# MSPM0L134X register map
Vendor: Texas Instruments; File version: This preliminary header file does not have a version number - build date: 2023-02-21 16:43:37
ARM Device
CPU: CM0 r0p1, little endian, MPU, no FPU, 3 interrupt priority bits
Registers are 32-bit, read-write, reset 0x0 unless marked. A register's access mark holds for its fields unless they carry their own. Offsets are from the block's base; lines under a group give offsets from that group; [hi:lo] are bit positions; {n}, {i} and the like mark numbered series; 'fields as' and 'values as' point back to an identical list; <NAME> marks a mode.

## Memory map
0x40004000 ADC0 size 0x2000 — PERIPHERALREGION
0x40008000 COMP0 size 0x1F00 — PERIPHERALREGION
0x40020000 OPA0 size 0x1F00 — PERIPHERALREGION
0x40022000 OPA1 size 0x1F00 — PERIPHERALREGION
0x40030000 VREF size 0x1F00 — PERIPHERALREGION
0x40080000 WWDT0 size 0x1500 — WWDT
0x40084000 TIMG0 size 0x1F00 — PERIPHERALREGION
0x40086000 TIMG1 size 0x1F00 — PERIPHERALREGION
0x40088000 TIMG2 size 0x1F00 — PERIPHERALREGION
0x4008C000 TIMG4 size 0x1F00 — PERIPHERALREGION
0x400A0000 GPIOA size 0x1F00 — PERIPHERALREGION
0x400AF000 SYSCTL size 0x2C64 — mem_map
0x400C7000 DEBUGSS size 0x1F00 — DSSM
0x400CD000 FLASHCTL size 0x2000 — F65NW
0x400F0000 I2C0 size 0x1F00 — PERIPHERALREGION
0x400F2000 I2C1 size 0x1F00 — PERIPHERALREGION
0x40100000 UART1 size 0x1F00 — PERIPHERALREGION
0x40108000 UART0 size 0x1F00 — PERIPHERALREGION
0x40400000 CPUSS size 0x1F00 — CPUSSMMR
0x40424000 WUC size 0x500 — PERIPHERALREGION
0x40428000 IOMUX size 0x2000 — PERIPHERALREGION
0x4042A000 DMA size 0x1F00 — PERIPHERALREGION
0x40440000 CRC size 0x2000 — PERIPHERALREGION
0x40468000 SPI0 size 0x1F00 — PERIPHERALREGION
0x4055A000 ADC0_SVT size 0x1000 — PERIPHERALREGIONSVT

## VREF — PERIPHERALREGION
Base 0x40030000
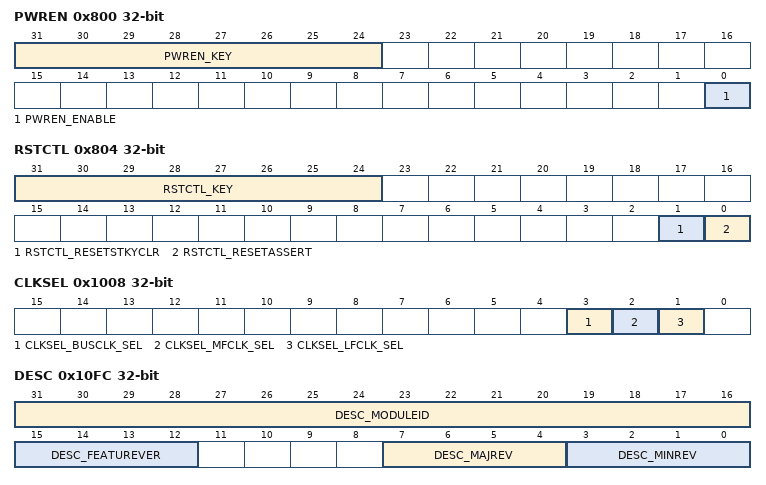
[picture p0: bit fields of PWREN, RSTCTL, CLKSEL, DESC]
0x800 PWREN — Power enable
  [31:24] PWREN_KEY wo — KEY to allow Power State Change
    38=PWREN_KEY_UNLOCK_W (_TO_UNLOCK_W_)
  [0] PWREN_ENABLE — Enable the power
    0=PWREN_ENABLE_DISABLE (DISABLE); 1=PWREN_ENABLE_ENABLE (ENABLE)
0x804 RSTCTL wo — Reset Control
  [31:24] RSTCTL_KEY — Unlock key
    177=RSTCTL_KEY_UNLOCK_W (_TO_UNLOCK_W_)
  [1] RSTCTL_RESETSTKYCLR — Clear the RESETSTKY bit in the STAT register
    0=RSTCTL_RESETSTKYCLR_NOP (NOP); 1=RSTCTL_RESETSTKYCLR_CLR (CLR)
  [0] RSTCTL_RESETASSERT — Assert reset to the peripheral
    0=RSTCTL_RESETASSERT_NOP (NOP); 1=RSTCTL_RESETASSERT_ASSERT (ASSERT)
0x814 STAT ro — Status Register
  [16] STAT_RESETSTKY — This bit indicates, if the peripheral was reset, since this bit was cleared by RESETSTKYCLR in the RSTCTL register
    0=STAT_RESETSTKY_NORES (NORES); 1=STAT_RESETSTKY_RESET (RESET)
0x1000 CLKDIV — Clock Divider
  [2:0] CLKDIV_RATIO — Selects divide ratio of module clock
0x1008 CLKSEL — Clock Selection
  [3] CLKSEL_BUSCLK_SEL — Selects BUSCLK as clock source if enabled
  [2] CLKSEL_MFCLK_SEL — Selects MFCLK as clock source if enabled
  [1] CLKSEL_LFCLK_SEL — Selects LFCLK as clock source if enabled
0x10FC DESC ro — Module Description
  [31:16] DESC_MODULEID — Module identification contains a unique peripheral identification number. The assignments are maintained in a central database for all of the platform modules to ensure uniqueness.
  [15:12] DESC_FEATUREVER — Feature Set for the module *instance*
  [7:4] DESC_MAJREV — Major rev of the IP
  [3:0] DESC_MINREV — Minor rev of the IP
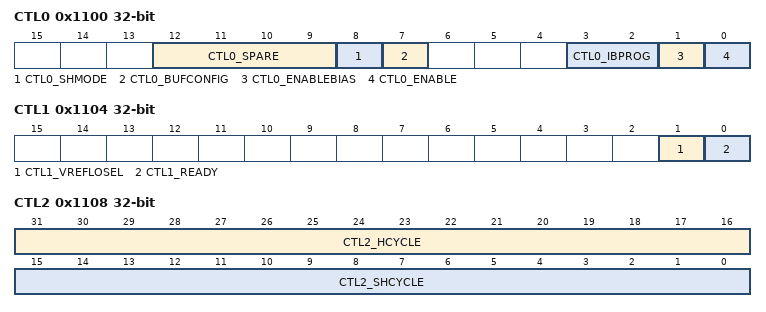
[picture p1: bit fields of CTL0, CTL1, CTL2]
0x1100 CTL0 — Control 0
  [12:9] CTL0_SPARE — These bits are reserved
  [8] CTL0_SHMODE — This bit enable sample and hold mode
    0=CTL0_SHMODE_DISABLE (DISABLE); 1=CTL0_SHMODE_ENABLE (ENABLE)
  [7] CTL0_BUFCONFIG — These bits configure output buffer.
    0=CTL0_BUFCONFIG_OUTPUT2P5V (HV); 1=CTL0_BUFCONFIG_OUTPUT1P4V (LV)
  [3:2] CTL0_IBPROG — There bits configure current bias.
    0=CTL0_IBPROG_NOMIBIAS (NOMIBIAS); 1=CTL0_IBPROG_IBPROG01 (IBPROG01); 2=CTL0_IBPROG_IBPROG10 (IBPROG10); 3=CTL0_IBPROG_IBPROG11 (IBPROG11)
  [1] CTL0_ENABLEBIAS — This bit enables the VREF Bias.
    0=CTL0_ENABLEBIAS_DISABLE (DISABLE); 1=CTL0_ENABLEBIAS_ENABLE (ENABLE)
  [0] CTL0_ENABLE — This bit enables the VREF module.
    0=CTL0_ENABLE_DISABLE (DISABLE); 1=CTL0_ENABLE_ENABLE (ENABLE)
0x1104 CTL1 — Control 1
  [1] CTL1_VREFLOSEL — This bit select VREFLO pin
  [0] CTL1_READY ro — These bits defines status of VREF
    0=CTL1_READY_NOTRDY (NOTRDY); 1=CTL1_READY_RDY (RDY)
0x1108 CTL2 — Control 2
  [31:16] CTL2_HCYCLE — Hold cycle count
  [15:0] CTL2_SHCYCLE — Sample and hold cycle count

## Licence text in the file
Copyright (C) 2023 Texas Instruments Incorporated - http://www.ti.com/ Redistribution and use in source and binary forms, with or without modification, are permitted provided that the following conditions are met: Redistributions of source code must retain the above copyright notice, this list of conditions and the following disclaimer. Redistributions in binary form must reproduce the above copyright notice, this list of conditions and the following disclaimer in the documentation and/or other materials provided with the distribution. Neither the name of Texas Instruments Incorporated nor the names of its contributors may be used to endorse or promote products derived from this software without specific prior written permission. THIS SOFTWARE IS PROVIDED BY THE COPYRIGHT HOLDERS AND CONTRIBUTORS "AS IS" AND ANY EXPRESS OR IMPLIED WARRANTIES, INCLUDING, BUT NOT LIMITED TO, THE IMPLIED WARRANTIES OF MERCHANTABILITY AND FITNESS FOR A PARTICULAR PURPOSE ARE DISCLAIMED. IN NO EVENT SHALL THE COPYRIGHT OWNER OR CONTRIBUTORS BE LIABLE FOR ANY DIRECT, INDIRECT, INCIDENTAL, SPECIAL, EXEMPLARY, OR CONSEQUENTIAL DAMAGES (INCLUDING, BUT NOT LIMITED TO, PROCUREMENT OF SUBSTITUTE GOODS OR SERVICES; LOSS OF USE, DATA, OR PROFITS; OR BUSINESS INTERRUPTION) HOWEVER CAUSED AND ON ANY THEORY OF LIABILITY, WHETHER IN CONTRACT, STRICT LIABILITY, OR TORT (INCLUDING NEGLIGENCE OR OTHERWISE) ARISING IN ANY WAY OUT OF THE USE OF THIS SOFTWARE, EVEN IF ADVISED OF THE POSSIBILITY OF SUCH DAMAGE.
